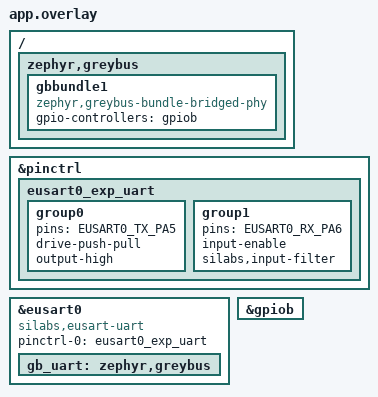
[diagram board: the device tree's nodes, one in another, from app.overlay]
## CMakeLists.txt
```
# SPDX-License-Identifier: Apache-2.0

cmake_minimum_required(VERSION 3.20.0)

find_package(Zephyr REQUIRED HINTS $ENV{ZEPHYR_BASE})

project(greybus-basic)

target_sources(app PRIVATE src/hdlc.c src/main.c)
```

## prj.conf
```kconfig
# Copyright (c) 2025 Ayush Singh, BeagleBoard.org
#
# SPDX-License-Identifier: Apache-2.0

CONFIG_GREYBUS=y

CONFIG_LOG=y
CONFIG_GREYBUS_LOG_LEVEL_DBG=y

CONFIG_SERIAL=y
CONFIG_GREYBUS_XPORT_UART_HDLC=y

CONFIG_GPIO=y
CONFIG_GPIO_GET_DIRECTION=y
CONFIG_GREYBUS_GPIO=y
```

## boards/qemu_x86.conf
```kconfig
# Copyright (c) 2025 Ayush Singh, BeagleBoard.org
#
# SPDX-License-Identifier: Apache-2.0

CONFIG_UART_LINE_CTRL=y
CONFIG_UART_INTERRUPT_DRIVEN=y
CONFIG_GREYBUS_UART=y

CONFIG_GREYBUS_LOOPBACK=y
CONFIG_GREYBUS_LOG_BACKEND=y

CONFIG_IMG_MANAGER=y
CONFIG_MCUBOOT_IMG_MANAGER=y

CONFIG_OPT3001=n
CONFIG_LIS2DH=n
CONFIG_LIS2DH_OPER_MODE_LOW_POWER=n
CONFIG_TI_HDC20XX=n
```

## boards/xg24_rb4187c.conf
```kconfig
CONFIG_UART_LINE_CTRL=y
CONFIG_UART_INTERRUPT_DRIVEN=y
CONFIG_GREYBUS_UART=y

CONFIG_BT=y
CONFIG_GREYBUS_BT_HCI=y

CONFIG_GREYBUS_LOOPBACK=y
CONFIG_GREYBUS_LOG_BACKEND=y

CONFIG_UART_CONSOLE=n
CONFIG_LOG_BACKEND_SWO=y
```

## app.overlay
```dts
/*
 * Copyright (c) 2025 Ayush Singh, BeagleBoard.org
 *
 * SPDX-License-Identifier: Apache-2.0
 */

/ {
	zephyr,greybus {
		gbbundle1 {
			status = "okay";
			compatible = "zephyr,greybus-bundle-bridged-phy";
			gpio-controllers = <&gpiob>;
		};
	};
};
&pinctrl {
	eusart0_exp_uart: eusart0_exp_uart {
		group0 {
			pins = <EUSART0_TX_PA5>;
			drive-push-pull;
			output-high;
		};

		group1 {
			pins = <EUSART0_RX_PA6>;
			input-enable;
			silabs,input-filter;
		};
	};
};

&eusart0 {
	compatible = "silabs,eusart-uart";
	pinctrl-0 = <&eusart0_exp_uart>;
	pinctrl-names = "default";
	status = "okay";
	
	gb_uart: zephyr,greybus {
		status = "okay";
	};
};

&gpiob {
	status = "okay";
};
```

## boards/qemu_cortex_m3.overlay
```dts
/*
 * Copyright (c) 2025 Ayush Singh, BeagleBoard.org
 *
 * SPDX-License-Identifier: Apache-2.0
 */

/ {
	zephyr,greybus {
		gbbundle1 {
			status = "okay";
			compatible = "zephyr,greybus-bundle-bridged-phy";
			uart-controllers = <&uart2>;
		};
	};
};
```

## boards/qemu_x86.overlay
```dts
/*
 * Copyright (c) 2025 Ayush Singh, BeagleBoard.org
 *
 * SPDX-License-Identifier: Apache-2.0
 */

/ {
	zephyr,greybus {
		gbbundle1 {
			status = "okay";
			compatible = "zephyr,greybus-bundle-bridged-phy";
			uart-controllers = <&uart1>;
		};
	};
};
```

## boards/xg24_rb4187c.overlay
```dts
/ {
	zephyr,greybus {
		//gbbundle1 {
		//	status = "okay";
		//	compatible = "zephyr,greybus-bundle-bridged-phy";
		//	uart-controllers = <&eusart1>;
		//};

	};
};

    &eusart0 {
	compatible = "silabs,eusart-uart";
        status = "okay";
    };

    &eusart1 {
	compatible = "silabs,eusart-uart";
	pinctrl-0 = <&eusart1_default>;
	pinctrl-names = "default";
	status = "okay";
	/delete-property/ cs-gpios;
    };
```

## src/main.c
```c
/*
 * Copyright (c) 2025 Ayush Singh BeagleBoard.org
 *
 * SPDX-License-Identifier: Apache-2.0
 */

#include <zephyr/drivers/uart.h>
#include <zephyr/logging/log.h>
#include <zephyr/sys/printk.h>

#include <greybus/greybus.h>

#ifdef CONFIG_PRINT_MANIFEST
#include "greybus-utils/manifest.h"
#endif // CONFIG_PRINT_MANIFEST

LOG_MODULE_REGISTER(main, CONFIG_GREYBUS_LOG_LEVEL);

// #define UART_DEVICE_NODE DT_CHOSEN(zephyr_bt_mon_uart)
// static const struct device *const uart_dev = DEVICE_DT_GET(UART_DEVICE_NODE);

int main(void)
{
#ifdef CONFIG_PRINT_MANIFEST
	static char manifest[1024];
	int ret = manifest_create(manifest, ARRAY_SIZE(manifest));
	LOG_DBG("Manifest Size: %d\n", ret);

	manifest_print(manifest);
#endif // CONFIG_PRINT_MANIFEST

	// if (!device_is_ready(uart_dev)) {
	// 	LOG_ERR("UART device not ready");
	// 	return -ENODEV;
	// }

	k_sleep(K_FOREVER);

	return 0;
}
```

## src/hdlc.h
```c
/* SPDX-License-Identifier: Apache-2.0 */
/*
 * Copyright (c) 2023 Ayush Singh <ayushdevel1325@gmail.com>
 */

#ifndef _HDLC_H_
#define _HDLC_H_

#include <stdint.h>
#include <zephyr/device.h>
#include <greybus/greybus_messages.h>

#define HDLC_MAX_BLOCK_SIZE 256

#define ADDRESS_GREYBUS 0x01
#define ADDRESS_DBG     0x02
#define ADDRESS_CONTROL 0x03
#define ADDRESS_MCUMGR  0x04

/*
 * Calback to process a received HDLC frame
 *
 * @param payload
 * @param payload len
 * @param HDLC address
 *
 * @return Negative in case of error
 */
typedef int (*hdlc_process_frame_callback)(const void *, size_t, uint8_t);

/*
 * Callback to send HDLC data
 *
 * @param buffer
 * @param buffer length
 *
 * @return Number of bytes sent, negative in case of error
 */
typedef int (*hdlc_send_frame_callback)(const uint8_t *, size_t);

/*
 * Initialize internal HDLC stuff
 *
 * @return 0 if successful. Negative in case of error.
 */
int hdlc_init(hdlc_process_frame_callback process_cb, hdlc_send_frame_callback send_cb);

/*
 * Submit an HDLC Block synchronously
 *
 * @param buffer
 * @param buffer_length
 * @param address
 * @param control
 *
 * @return block size (>= 0) if successful. Negative in case of error
 */
int hdlc_block_send_sync(const uint8_t *buffer, size_t buffer_len, uint8_t address,
			 uint8_t control);

/*
 * Get a buffer to write HDLC message received for processing. Make HDLC transport agnostic.
 *
 * @param the pointer to underlying buffer which can be used to write.
 *
 * @return number of bytes that can be written
 */
uint32_t hdlc_rx_start(uint8_t **buffer);

/*
 * Finish writing to rx buffer. Also queues rx buffer for processing
 *
 * @param number of bytes written
 *
 * @return 0 if successful. Negative in case of error.
 */
int hdlc_rx_finish(uint32_t written);

/*
 * Send a greybus message over HDLC
 *
 * @param Greybus message
 */
static inline int gb_message_hdlc_send(struct gb_message *msg, uint16_t cport)
{
	char buffer[HDLC_MAX_BLOCK_SIZE];

	memcpy(buffer, &sys_cpu_to_le16(cport), sizeof(cport));
	memcpy(&buffer[sizeof(cport)], &msg->header, sizeof(struct gb_operation_msg_hdr));
	memcpy(&buffer[sizeof(struct gb_operation_msg_hdr) + sizeof(cport)], msg->payload,
	       gb_message_payload_len(msg));

	hdlc_block_send_sync(buffer, msg->header.size + sizeof(cport), ADDRESS_GREYBUS, 0x03);

	return 0;
}

#endif
```
